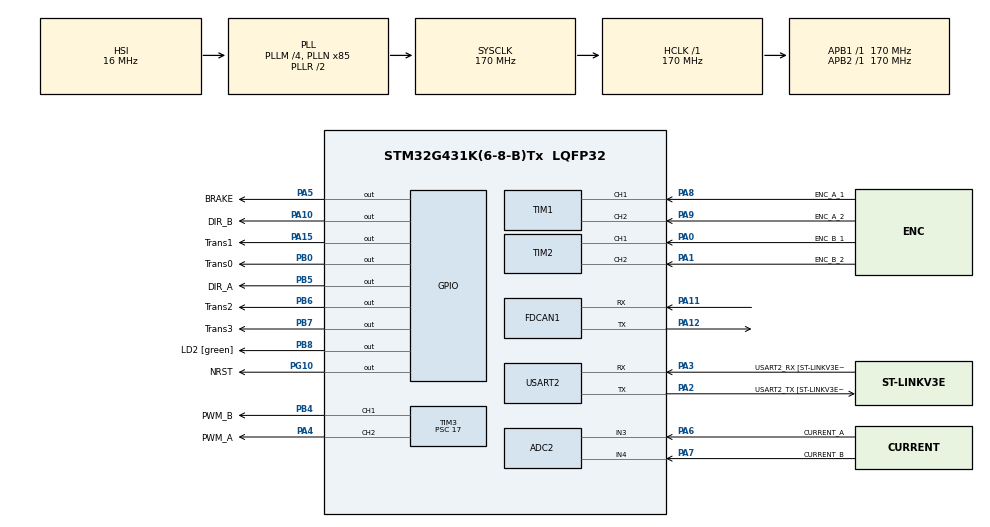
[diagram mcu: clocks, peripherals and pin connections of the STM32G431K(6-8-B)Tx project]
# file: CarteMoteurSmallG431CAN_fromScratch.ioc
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ADC2.Channel-0\#ChannelRegularConversion=ADC_CHANNEL_3
ADC2.ContinuousConvMode=DISABLE
ADC2.EnableAnalogWatchDog1=false
ADC2.NbrOfConversion=1
ADC2.NbrOfConversionFlag=1
ADC2.OffsetNumber-0\#ChannelRegularConversion=ADC_OFFSET_NONE
ADC2.Rank-0\#ChannelRegularConversion=1
ADC2.SamplingTime-0\#ChannelRegularConversion=ADC_SAMPLETIME_2CYCLES_5
Dma.ADC2.0.Direction=DMA_PERIPH_TO_MEMORY
Dma.ADC2.0.EventEnable=DISABLE
Dma.ADC2.0.Instance=DMA1_Channel1
Dma.ADC2.0.MemDataAlignment=DMA_MDATAALIGN_HALFWORD
Dma.ADC2.0.MemInc=DMA_MINC_ENABLE
Dma.ADC2.0.Mode=DMA_CIRCULAR
Dma.ADC2.0.PeriphDataAlignment=DMA_PDATAALIGN_HALFWORD
Dma.ADC2.0.PeriphInc=DMA_PINC_DISABLE
Dma.ADC2.0.Polarity=HAL_DMAMUX_REQ_GEN_RISING
Dma.ADC2.0.Priority=DMA_PRIORITY_LOW
Dma.ADC2.0.RequestNumber=1
Dma.ADC2.0.SignalID=NONE
Dma.ADC2.0.SyncEnable=DISABLE
Dma.ADC2.0.SyncPolarity=HAL_DMAMUX_SYNC_NO_EVENT
Dma.ADC2.0.SyncRequestNumber=1
Dma.ADC2.0.SyncSignalID=NONE
Dma.Request0=ADC2
FDCAN1.AutoRetransmission=ENABLE
FDCAN1.CalculateBaudRateNominal=1000000
FDCAN1.CalculateTimeBitNominal=1000
FDCAN1.CalculateTimeQuantumNominal=100.0
FDCAN1.NominalPrescaler=17
FDCAN1.NominalTimeSeg1=4
FDCAN1.NominalTimeSeg2=5
Mcu.Family=STM32G4
Mcu.Name=STM32G431K(6-8-B)Tx
Mcu.Package=LQFP32
Mcu.UserConstants=TwicePer100Hz,85
NVIC.ADC1_2_IRQn=true\:0\:0\:false\:false\:true\:true\:true\:true
NVIC.DMA1_Channel1_IRQn=true\:0\:0\:false\:false\:true\:false\:true\:true
NVIC.FDCAN1_IT0_IRQn=true\:0\:0\:false\:false\:true\:true\:true\:true
NVIC.FDCAN1_IT1_IRQn=true\:0\:0\:false\:false\:true\:true\:true\:true
NVIC.PriorityGroup=NVIC_PRIORITYGROUP_4
NVIC.TIM1_BRK_TIM15_IRQn=true\:0\:0\:false\:false\:true\:true\:true\:true
PA0.GPIO_Label=ENC_B_1
PA0.GPIO_PuPd=GPIO_PULLUP
PA0.GPIO_Speed=GPIO_SPEED_FREQ_MEDIUM
PA0.Signal=S_TIM2_CH1
PA1.GPIO_Label=ENC_B_2
PA1.GPIO_PuPd=GPIO_PULLUP
PA1.GPIO_Speed=GPIO_SPEED_FREQ_MEDIUM
PA1.Signal=S_TIM2_CH2
PA10.GPIO_Label=DIR_B
PA10.Signal=GPIO_Output
PA11.Mode=FDCAN_Activate
PA11.Signal=FDCAN1_RX
PA12.Mode=FDCAN_Activate
PA12.Signal=FDCAN1_TX
PA13.GPIO_Label=T_SWDIO
PA13.Mode=Serial_Wire
PA13.Signal=SYS_JTMS-SWDIO
PA14.GPIO_Label=T_SWCLK
PA14.Mode=Serial_Wire
PA14.Signal=SYS_JTCK-SWCLK
PA15.GPIO_Label=Trans1
PA15.Signal=GPIO_Output
PA2.GPIO_Label=USART2_TX [ST-LINKV3E_VCP_RX]
PA2.Mode=Asynchronous
PA2.Signal=USART2_TX
PA3.GPIO_Label=USART2_RX [ST-LINKV3E_VCP_TX]
PA3.Mode=Asynchronous
PA3.Signal=USART2_RX
PA4.GPIO_Label=PWM_A
PA4.GPIO_PuPd=GPIO_PULLUP
PA4.GPIO_Speed=GPIO_SPEED_FREQ_MEDIUM
PA4.Signal=S_TIM3_CH2
PA5.GPIO_Label=BRAKE
PA5.GPIO_PuPd=GPIO_NOPULL
PA5.Signal=GPIO_Output
PA6.GPIO_Label=CURRENT_A
PA6.Mode=IN3-Single-Ended
PA6.Signal=ADC2_IN3
PA7.GPIO_Label=CURRENT_B
PA7.Mode=IN4-Single-Ended
PA7.Signal=ADC2_IN4
PA8.GPIO_Label=ENC_A_1
PA8.GPIO_PuPd=GPIO_PULLUP
PA8.GPIO_Speed=GPIO_SPEED_FREQ_MEDIUM
PA8.Signal=S_TIM1_CH1
PA9.GPIO_Label=ENC_A_2
PA9.GPIO_PuPd=GPIO_PULLDOWN
PA9.GPIO_Speed=GPIO_SPEED_FREQ_MEDIUM
PA9.Signal=S_TIM1_CH2
PB0.GPIO_Label=Trans0
PB0.GPIO_PuPd=GPIO_NOPULL
PB0.Signal=GPIO_Output
PB3.GPIO_Label=T_SWO
PB3.Signal=SYS_JTDO-SWO
PB4.GPIO_Label=PWM_B
PB4.GPIO_PuPd=GPIO_PULLUP
PB4.GPIO_Speed=GPIO_SPEED_FREQ_MEDIUM
PB4.Signal=S_TIM3_CH1
PB5.GPIO_Label=DIR_A
PB5.Signal=GPIO_Output
PB6.GPIO_Label=Trans2
PB6.Signal=GPIO_Output
PB7.GPIO_Label=Trans3
PB7.Signal=GPIO_Output
PB8-BOOT0.GPIO_Label=LD2 [green]
PB8-BOOT0.Signal=GPIO_Output
PG10-NRST.GPIO_Label=NRST
PG10-NRST.Signal=GPIO_Output
ProjectManager.HeapSize=0x200
ProjectManager.StackSize=0x400
ProjectManager.TargetToolchain=STM32CubeIDE
RCC.ADC12Freq_Value=170000000
RCC.AHBFreq_Value=170000000
RCC.APB1Freq_Value=170000000
RCC.APB1TimFreq_Value=170000000
RCC.APB2Freq_Value=170000000
RCC.APB2TimFreq_Value=170000000
RCC.CortexFreq_Value=170000000
RCC.EXTERNAL_CLOCK_VALUE=12288000
RCC.HCLKFreq_Value=170000000
RCC.HSE_VALUE=8000000
RCC.HSI48_VALUE=48000000
RCC.HSI_VALUE=16000000
RCC.LSE_VALUE=32768
RCC.PLLM=RCC_PLLM_DIV4
RCC.PLLN=85
RCC.SYSCLKFreq_VALUE=170000000
RCC.SYSCLKSource=RCC_SYSCLKSOURCE_PLLCLK
RCC.USBFreq_Value=170000000
RCC.VCOOutputFreq_Value=340000000
SH.S_TIM1_CH1.0=TIM1_CH1,Encoder_Interface
SH.S_TIM1_CH2.0=TIM1_CH2,Encoder_Interface
SH.S_TIM2_CH1.0=TIM2_CH1,Encoder_Interface
SH.S_TIM2_CH2.0=TIM2_CH2,Encoder_Interface
SH.S_TIM3_CH1.0=TIM3_CH1,PWM Generation1 CH1
SH.S_TIM3_CH2.0=TIM3_CH2,PWM Generation2 CH2
TIM1.AutoReloadPreload=TIM_AUTORELOAD_PRELOAD_ENABLE
TIM1.EncoderMode=TIM_ENCODERMODE_TI12
TIM15.AutoReloadPreload=TIM_AUTORELOAD_PRELOAD_ENABLE
TIM15.PeriodNoDither=170
TIM15.Prescaler=1000
TIM2.AutoReloadPreload=TIM_AUTORELOAD_PRELOAD_ENABLE
TIM2.CounterMode=TIM_COUNTERMODE_UP
TIM2.EncoderMode=TIM_ENCODERMODE_TI12
TIM3.AutoReloadPreload=TIM_AUTORELOAD_PRELOAD_ENABLE
TIM3.Channel-PWM\ Generation1\ CH1=TIM_CHANNEL_1
TIM3.Channel-PWM\ Generation2\ CH2=TIM_CHANNEL_2
TIM3.PeriodNoDither=256
TIM3.Prescaler=17
TIM7.PeriodNoDither=65535
TIM7.Prescaler=170
USART2.VirtualMode-Asynchronous=VM_ASYNC
USART2.WordLength=WORDLENGTH_8B
VP_SYS_VS_DBSignals.Mode=DisableDeadBatterySignals
VP_TIM15_VS_ClockSourceINT.Mode=Internal
VP_TIM7_VS_ClockSourceINT.Mode=Enable_Timer
board=NUCLEO-G431KB

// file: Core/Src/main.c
/* USER CODE BEGIN Header */
/**
  ******************************************************************************
  * @file           : main.c
  * @brief          : Main program body
  ******************************************************************************
  * @attention
  *
  * Copyright (c) 2024 STMicroelectronics.
  * All rights reserved.
  *
  * This software is licensed under terms that can be found in the LICENSE file
  * in the root directory of this software component.
  * If no LICENSE file comes with this software, it is provided AS-IS.
  *
  ******************************************************************************
  */
/* USER CODE END Header */
#include "main.h"

ADC_HandleTypeDef hadc2;
DMA_HandleTypeDef hdma_adc2;

FDCAN_HandleTypeDef hfdcan1;

TIM_HandleTypeDef htim1;
TIM_HandleTypeDef htim2;
TIM_HandleTypeDef htim3;
TIM_HandleTypeDef htim7;
TIM_HandleTypeDef htim15;

UART_HandleTypeDef huart2;

void SystemClock_Config(void);
static void MX_GPIO_Init(void);
static void MX_DMA_Init(void);
static void MX_TIM1_Init(void);
static void MX_TIM2_Init(void);
static void MX_TIM3_Init(void);
static void MX_USART2_UART_Init(void);
static void MX_FDCAN1_Init(void);
static void MX_TIM15_Init(void);
static void MX_TIM7_Init(void);
static void MX_ADC2_Init(void);

int main(void)
{

  /* MCU Configuration--------------------------------------------------------*/

  /* Reset of all peripherals, Initializes the Flash interface and the Systick. */
  HAL_Init();

  /* Configure the system clock */
  SystemClock_Config();

  /* Initialize all configured peripherals */
  MX_GPIO_Init();
  MX_DMA_Init();
  MX_TIM1_Init();
  MX_TIM2_Init();
  MX_TIM3_Init();
  MX_USART2_UART_Init();
  MX_FDCAN1_Init();
  MX_TIM15_Init();
  MX_TIM7_Init();
  MX_ADC2_Init();
  /* USER CODE BEGIN 2 */

	__HAL_TIM_SET_COMPARE(&htim3, TIM_CHANNEL_1, 0x0);
	__HAL_TIM_SET_COMPARE(&htim3, TIM_CHANNEL_2, 0x0);
	HAL_TIM_PWM_Start(&htim3, TIM_CHANNEL_1);
	HAL_TIM_PWM_Start(&htim3, TIM_CHANNEL_2);

	HAL_TIM_Encoder_Start(&htim1, TIM_CHANNEL_ALL);
	HAL_TIM_Encoder_Start(&htim2, TIM_CHANNEL_ALL);

  setup();
  /* USER CODE END 2 */

  /* Infinite loop */
  /* USER CODE BEGIN WHILE */
  while (1)
  {
	  /*HAL_GPIO_WritePin(BRAKE_GPIO_Port, BRAKE_Pin, GPIO_PIN_RESET);
	  HAL_GPIO_WritePin(BRAKE_B_GPIO_Port, BRAKE_B_Pin, GPIO_PIN_RESET);

	  HAL_Delay(10);
	  HAL_GPIO_WritePin(BRAKE_GPIO_Port, BRAKE_Pin, GPIO_PIN_SET);
	  HAL_GPIO_WritePin(BRAKE_B_GPIO_Port, BRAKE_B_Pin, GPIO_PIN_SET);

	  HAL_Delay(10);*/
	  loop(&htim3, &htim15, &huart2, &hfdcan1, &hadc2);
    /* USER CODE END WHILE */

  }
}

void SystemClock_Config(void)
{
  RCC_OscInitTypeDef RCC_OscInitStruct = {0};
  RCC_ClkInitTypeDef RCC_ClkInitStruct = {0};

  /** Configure the main internal regulator output voltage
  */
  HAL_PWREx_ControlVoltageScaling(PWR_REGULATOR_VOLTAGE_SCALE1_BOOST);

  /** Initializes the RCC Oscillators according to the specified parameters
  * in the RCC_OscInitTypeDef structure.
  */
  RCC_OscInitStruct.OscillatorType = RCC_OSCILLATORTYPE_HSI;
  RCC_OscInitStruct.HSIState = RCC_HSI_ON;
  RCC_OscInitStruct.HSICalibrationValue = RCC_HSICALIBRATION_DEFAULT;
  RCC_OscInitStruct.PLL.PLLState = RCC_PLL_ON;
  RCC_OscInitStruct.PLL.PLLSource = RCC_PLLSOURCE_HSI;
  RCC_OscInitStruct.PLL.PLLM = RCC_PLLM_DIV4;
  RCC_OscInitStruct.PLL.PLLN = 85;
  RCC_OscInitStruct.PLL.PLLP = RCC_PLLP_DIV2;
  RCC_OscInitStruct.PLL.PLLQ = RCC_PLLQ_DIV2;
  RCC_OscInitStruct.PLL.PLLR = RCC_PLLR_DIV2;
  if (HAL_RCC_OscConfig(&RCC_OscInitStruct) != HAL_OK)
  {
    Error_Handler();
  }

  /** Initializes the CPU, AHB and APB buses clocks
  */
  RCC_ClkInitStruct.ClockType = RCC_CLOCKTYPE_HCLK|RCC_CLOCKTYPE_SYSCLK
                              |RCC_CLOCKTYPE_PCLK1|RCC_CLOCKTYPE_PCLK2;
  RCC_ClkInitStruct.SYSCLKSource = RCC_SYSCLKSOURCE_PLLCLK;
  RCC_ClkInitStruct.AHBCLKDivider = RCC_SYSCLK_DIV1;
  RCC_ClkInitStruct.APB1CLKDivider = RCC_HCLK_DIV1;
  RCC_ClkInitStruct.APB2CLKDivider = RCC_HCLK_DIV1;

  if (HAL_RCC_ClockConfig(&RCC_ClkInitStruct, FLASH_LATENCY_4) != HAL_OK)
  {
    Error_Handler();
  }
}

static void MX_ADC2_Init(void)
{

  ADC_ChannelConfTypeDef sConfig = {0};

  /** Common config
  */
  hadc2.Instance = ADC2;
  hadc2.Init.ClockPrescaler = ADC_CLOCK_SYNC_PCLK_DIV4;
  hadc2.Init.Resolution = ADC_RESOLUTION_12B;
  hadc2.Init.DataAlign = ADC_DATAALIGN_RIGHT;
  hadc2.Init.GainCompensation = 0;
  hadc2.Init.ScanConvMode = ADC_SCAN_DISABLE;
  hadc2.Init.EOCSelection = ADC_EOC_SINGLE_CONV;
  hadc2.Init.LowPowerAutoWait = DISABLE;
  hadc2.Init.ContinuousConvMode = DISABLE;
  hadc2.Init.NbrOfConversion = 1;
  hadc2.Init.DiscontinuousConvMode = DISABLE;
  hadc2.Init.ExternalTrigConv = ADC_SOFTWARE_START;
  hadc2.Init.ExternalTrigConvEdge = ADC_EXTERNALTRIGCONVEDGE_NONE;
  hadc2.Init.DMAContinuousRequests = DISABLE;
  hadc2.Init.Overrun = ADC_OVR_DATA_PRESERVED;
  hadc2.Init.OversamplingMode = DISABLE;
  if (HAL_ADC_Init(&hadc2) != HAL_OK)
  {
    Error_Handler();
  }

  /** Configure Regular Channel
  */
  sConfig.Channel = ADC_CHANNEL_3;
  sConfig.Rank = ADC_REGULAR_RANK_1;
  sConfig.SamplingTime = ADC_SAMPLETIME_2CYCLES_5;
  sConfig.SingleDiff = ADC_SINGLE_ENDED;
  sConfig.OffsetNumber = ADC_OFFSET_NONE;
  sConfig.Offset = 0;
  if (HAL_ADC_ConfigChannel(&hadc2, &sConfig) != HAL_OK)
  {
    Error_Handler();
  }

}

static void MX_FDCAN1_Init(void)
{

  hfdcan1.Instance = FDCAN1;
  hfdcan1.Init.ClockDivider = FDCAN_CLOCK_DIV1;
  hfdcan1.Init.FrameFormat = FDCAN_FRAME_CLASSIC;
  hfdcan1.Init.Mode = FDCAN_MODE_NORMAL;
  hfdcan1.Init.AutoRetransmission = ENABLE;
  hfdcan1.Init.TransmitPause = DISABLE;
  hfdcan1.Init.ProtocolException = DISABLE;
  hfdcan1.Init.NominalPrescaler = 17; //17: 1Mbit, 34: 500k
  hfdcan1.Init.NominalSyncJumpWidth = 1;
  hfdcan1.Init.NominalTimeSeg1 = 4;
  hfdcan1.Init.NominalTimeSeg2 = 5;
  hfdcan1.Init.DataPrescaler = 1;
  hfdcan1.Init.DataSyncJumpWidth = 1;
  hfdcan1.Init.DataTimeSeg1 = 1;
  hfdcan1.Init.DataTimeSeg2 = 1;
  hfdcan1.Init.StdFiltersNbr = 0;
  hfdcan1.Init.ExtFiltersNbr = 0;
  hfdcan1.Init.TxFifoQueueMode = FDCAN_TX_FIFO_OPERATION;
  if (HAL_FDCAN_Init(&hfdcan1) != HAL_OK)
  {
    Error_Handler();
  }

}

static void MX_TIM1_Init(void)
{

  TIM_Encoder_InitTypeDef sConfig = {0};
  TIM_MasterConfigTypeDef sMasterConfig = {0};

  htim1.Instance = TIM1;
  htim1.Init.Prescaler = 0;
  htim1.Init.CounterMode = TIM_COUNTERMODE_UP;
  htim1.Init.Period = 65535;
  htim1.Init.ClockDivision = TIM_CLOCKDIVISION_DIV1;
  htim1.Init.RepetitionCounter = 0;
  htim1.Init.AutoReloadPreload = TIM_AUTORELOAD_PRELOAD_ENABLE;
  sConfig.EncoderMode = TIM_ENCODERMODE_TI12;
  sConfig.IC1Polarity = TIM_ICPOLARITY_RISING;
  sConfig.IC1Selection = TIM_ICSELECTION_DIRECTTI;
  sConfig.IC1Prescaler = TIM_ICPSC_DIV1;
  sConfig.IC1Filter = 0;
  sConfig.IC2Polarity = TIM_ICPOLARITY_RISING;
  sConfig.IC2Selection = TIM_ICSELECTION_DIRECTTI;
  sConfig.IC2Prescaler = TIM_ICPSC_DIV1;
  sConfig.IC2Filter = 0;
  if (HAL_TIM_Encoder_Init(&htim1, &sConfig) != HAL_OK)
  {
    Error_Handler();
  }
  sMasterConfig.MasterOutputTrigger = TIM_TRGO_RESET;
  sMasterConfig.MasterOutputTrigger2 = TIM_TRGO2_RESET;
  sMasterConfig.MasterSlaveMode = TIM_MASTERSLAVEMODE_DISABLE;
  if (HAL_TIMEx_MasterConfigSynchronization(&htim1, &sMasterConfig) != HAL_OK)
  {
    Error_Handler();
  }

}

static void MX_TIM2_Init(void)
{

  TIM_Encoder_InitTypeDef sConfig = {0};
  TIM_MasterConfigTypeDef sMasterConfig = {0};

  htim2.Instance = TIM2;
  htim2.Init.Prescaler = 0;
  htim2.Init.CounterMode = TIM_COUNTERMODE_UP;
  htim2.Init.Period = 4294967295;
  htim2.Init.ClockDivision = TIM_CLOCKDIVISION_DIV1;
  htim2.Init.AutoReloadPreload = TIM_AUTORELOAD_PRELOAD_ENABLE;
  sConfig.EncoderMode = TIM_ENCODERMODE_TI12;
  sConfig.IC1Polarity = TIM_ICPOLARITY_RISING;
  sConfig.IC1Selection = TIM_ICSELECTION_DIRECTTI;
  sConfig.IC1Prescaler = TIM_ICPSC_DIV1;
  sConfig.IC1Filter = 0;
  sConfig.IC2Polarity = TIM_ICPOLARITY_RISING;
  sConfig.IC2Selection = TIM_ICSELECTION_DIRECTTI;
  sConfig.IC2Prescaler = TIM_ICPSC_DIV1;
  sConfig.IC2Filter = 0;
  if (HAL_TIM_Encoder_Init(&htim2, &sConfig) != HAL_OK)
  {
    Error_Handler();
  }
  sMasterConfig.MasterOutputTrigger = TIM_TRGO_RESET;
  sMasterConfig.MasterSlaveMode = TIM_MASTERSLAVEMODE_DISABLE;
  if (HAL_TIMEx_MasterConfigSynchronization(&htim2, &sMasterConfig) != HAL_OK)
  {
    Error_Handler();
  }

}

static void MX_TIM3_Init(void)
{

  TIM_MasterConfigTypeDef sMasterConfig = {0};
  TIM_OC_InitTypeDef sConfigOC = {0};

  htim3.Instance = TIM3;
  htim3.Init.Prescaler = 17;
  htim3.Init.CounterMode = TIM_COUNTERMODE_UP;
  htim3.Init.Period = 256;
  htim3.Init.ClockDivision = TIM_CLOCKDIVISION_DIV1;
  htim3.Init.AutoReloadPreload = TIM_AUTORELOAD_PRELOAD_ENABLE;
  if (HAL_TIM_PWM_Init(&htim3) != HAL_OK)
  {
    Error_Handler();
  }
  sMasterConfig.MasterOutputTrigger = TIM_TRGO_RESET;
  sMasterConfig.MasterSlaveMode = TIM_MASTERSLAVEMODE_DISABLE;
  if (HAL_TIMEx_MasterConfigSynchronization(&htim3, &sMasterConfig) != HAL_OK)
  {
    Error_Handler();
  }
  sConfigOC.OCMode = TIM_OCMODE_PWM1;
  sConfigOC.Pulse = 0;
  sConfigOC.OCPolarity = TIM_OCPOLARITY_HIGH;
  sConfigOC.OCFastMode = TIM_OCFAST_DISABLE;
  if (HAL_TIM_PWM_ConfigChannel(&htim3, &sConfigOC, TIM_CHANNEL_1) != HAL_OK)
  {
    Error_Handler();
  }
  if (HAL_TIM_PWM_ConfigChannel(&htim3, &sConfigOC, TIM_CHANNEL_2) != HAL_OK)
  {
    Error_Handler();
  }
  HAL_TIM_MspPostInit(&htim3);

}

static void MX_TIM7_Init(void)
{

  TIM_MasterConfigTypeDef sMasterConfig = {0};

  htim7.Instance = TIM7;
  htim7.Init.Prescaler = 170;
  htim7.Init.CounterMode = TIM_COUNTERMODE_UP;
  htim7.Init.Period = 65535;
  htim7.Init.AutoReloadPreload = TIM_AUTORELOAD_PRELOAD_DISABLE;
  if (HAL_TIM_Base_Init(&htim7) != HAL_OK)
  {
    Error_Handler();
  }
  sMasterConfig.MasterOutputTrigger = TIM_TRGO_RESET;
  sMasterConfig.MasterSlaveMode = TIM_MASTERSLAVEMODE_DISABLE;
  if (HAL_TIMEx_MasterConfigSynchronization(&htim7, &sMasterConfig) != HAL_OK)
  {
    Error_Handler();
  }

}

static void MX_TIM15_Init(void)
{

  TIM_ClockConfigTypeDef sClockSourceConfig = {0};
  TIM_MasterConfigTypeDef sMasterConfig = {0};

  htim15.Instance = TIM15;
  htim15.Init.Prescaler = 3313; // 170MHz / 3314 / 171 ≈ 300Hz
  htim15.Init.CounterMode = TIM_COUNTERMODE_UP;
  htim15.Init.Period = 170;
  htim15.Init.ClockDivision = TIM_CLOCKDIVISION_DIV1;
  htim15.Init.RepetitionCounter = 0;
  htim15.Init.AutoReloadPreload = TIM_AUTORELOAD_PRELOAD_ENABLE;
  if (HAL_TIM_Base_Init(&htim15) != HAL_OK)
  {
    Error_Handler();
  }
  sClockSourceConfig.ClockSource = TIM_CLOCKSOURCE_INTERNAL;
  if (HAL_TIM_ConfigClockSource(&htim15, &sClockSourceConfig) != HAL_OK)
  {
    Error_Handler();
  }
  sMasterConfig.MasterOutputTrigger = TIM_TRGO_RESET;
  sMasterConfig.MasterSlaveMode = TIM_MASTERSLAVEMODE_DISABLE;
  if (HAL_TIMEx_MasterConfigSynchronization(&htim15, &sMasterConfig) != HAL_OK)
  {
    Error_Handler();
  }

}

static void MX_USART2_UART_Init(void)
{

  huart2.Instance = USART2;
  huart2.Init.BaudRate = 115200;
  huart2.Init.WordLength = UART_WORDLENGTH_8B;
  huart2.Init.StopBits = UART_STOPBITS_1;
  huart2.Init.Parity = UART_PARITY_NONE;
  huart2.Init.Mode = UART_MODE_TX_RX;
  huart2.Init.HwFlowCtl = UART_HWCONTROL_NONE;
  huart2.Init.OverSampling = UART_OVERSAMPLING_16;
  huart2.Init.OneBitSampling = UART_ONE_BIT_SAMPLE_DISABLE;
  huart2.Init.ClockPrescaler = UART_PRESCALER_DIV1;
  huart2.AdvancedInit.AdvFeatureInit = UART_ADVFEATURE_NO_INIT;
  if (HAL_UART_Init(&huart2) != HAL_OK)
  {
    Error_Handler();
  }
  if (HAL_UARTEx_SetTxFifoThreshold(&huart2, UART_TXFIFO_THRESHOLD_1_8) != HAL_OK)
  {
    Error_Handler();
  }
  if (HAL_UARTEx_SetRxFifoThreshold(&huart2, UART_RXFIFO_THRESHOLD_1_8) != HAL_OK)
  {
    Error_Handler();
  }
  if (HAL_UARTEx_DisableFifoMode(&huart2) != HAL_OK)
  {
    Error_Handler();
  }

}

static void MX_DMA_Init(void)
{

  /* DMA controller clock enable */
  __HAL_RCC_DMAMUX1_CLK_ENABLE();
  __HAL_RCC_DMA1_CLK_ENABLE();

  /* DMA interrupt init */
  /* DMA1_Channel1_IRQn interrupt configuration */
  HAL_NVIC_SetPriority(DMA1_Channel1_IRQn, 0, 0);
  HAL_NVIC_EnableIRQ(DMA1_Channel1_IRQn);

}

static void MX_GPIO_Init(void)
{
  GPIO_InitTypeDef GPIO_InitStruct = {0};

  /* GPIO Ports Clock Enable */
  __HAL_RCC_GPIOG_CLK_ENABLE();
  __HAL_RCC_GPIOA_CLK_ENABLE();
  __HAL_RCC_GPIOB_CLK_ENABLE();

  /*Configure GPIO pin Output Level */
  HAL_GPIO_WritePin(NRST_GPIO_Port, NRST_Pin, GPIO_PIN_RESET);

  /*Configure GPIO pin Output Level */
  HAL_GPIO_WritePin(GPIOA, BRAKE_Pin|DIR_B_Pin|Trans1_Pin, GPIO_PIN_RESET);

  /*Configure GPIO pin Output Level */
  HAL_GPIO_WritePin(GPIOB, Trans0_Pin|DIR_A_Pin|Trans2_Pin|Trans3_Pin
                          |LD2_Pin, GPIO_PIN_RESET);

  /*Configure GPIO pin : NRST_Pin */
  GPIO_InitStruct.Pin = NRST_Pin;
  GPIO_InitStruct.Mode = GPIO_MODE_OUTPUT_PP;
  GPIO_InitStruct.Pull = GPIO_NOPULL;
  GPIO_InitStruct.Speed = GPIO_SPEED_FREQ_LOW;
  HAL_GPIO_Init(NRST_GPIO_Port, &GPIO_InitStruct);

  /*Configure GPIO pins : BRAKE_Pin DIR_B_Pin Trans1_Pin */
  GPIO_InitStruct.Pin = BRAKE_Pin|DIR_B_Pin|Trans1_Pin;
  GPIO_InitStruct.Mode = GPIO_MODE_OUTPUT_PP;
  GPIO_InitStruct.Pull = GPIO_NOPULL;
  GPIO_InitStruct.Speed = GPIO_SPEED_FREQ_LOW;
  HAL_GPIO_Init(GPIOA, &GPIO_InitStruct);

  /*Configure GPIO pins : Trans0_Pin DIR_A_Pin Trans2_Pin Trans3_Pin
                           LD2_Pin */
  GPIO_InitStruct.Pin = Trans0_Pin|DIR_A_Pin|Trans2_Pin|Trans3_Pin
                          |LD2_Pin;
  GPIO_InitStruct.Mode = GPIO_MODE_OUTPUT_PP;
  GPIO_InitStruct.Pull = GPIO_NOPULL;
  GPIO_InitStruct.Speed = GPIO_SPEED_FREQ_LOW;
  HAL_GPIO_Init(GPIOB, &GPIO_InitStruct);

}

void Error_Handler(void)
{
  __disable_irq();
  while (1)
  {
  }
}
